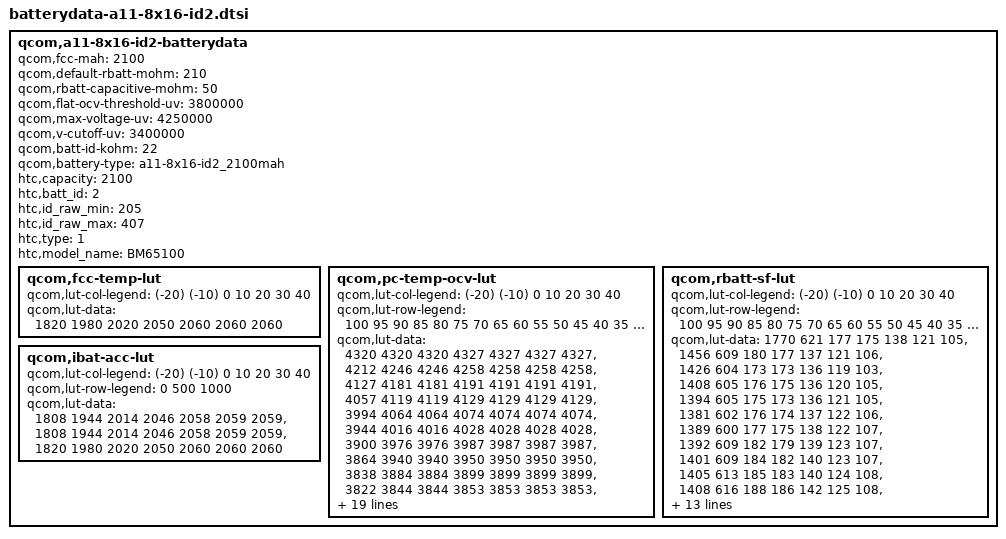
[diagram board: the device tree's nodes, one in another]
/* Copyright (c) 2013, The Linux Foundation. All rights reserved.
 *
 * This program is free software; you can redistribute it and/or modify
 * it under the terms of the GNU General Public License version 2 and
 * only version 2 as published by the Free Software Foundation.
 *
 * This program is distributed in the hope that it will be useful,
 * but WITHOUT ANY WARRANTY; without even the implied warranty of
 * MERCHANTABILITY or FITNESS FOR A PARTICULAR PURPOSE.  See the
 * GNU General Public License for more details.
 */

qcom,a11-8x16-id2-batterydata {
	qcom,fcc-mah = <2100>;
	qcom,default-rbatt-mohm = <210>;
	qcom,rbatt-capacitive-mohm = <50>;
	qcom,flat-ocv-threshold-uv = <3800000>;
	qcom,max-voltage-uv = <4250000>;
	qcom,v-cutoff-uv = <3400000>;
	qcom,batt-id-kohm = <22>;
	qcom,battery-type = "a11-8x16-id2_2100mah";
	htc,capacity = <2100>;
	htc,batt_id = <2>;
	htc,id_raw_min = <205>;
	htc,id_raw_max = <407>;
	htc,type = <1>;
	htc,model_name = "BM65100";

	qcom,fcc-temp-lut {
		qcom,lut-col-legend = <(-20) (-10) 0 10 20 30 40>;
		qcom,lut-data = <1820 1980 2020 2050 2060 2060 2060>;
	};

	qcom,pc-temp-ocv-lut {
		qcom,lut-col-legend = <(-20) (-10) 0 10 20 30 40>;
		qcom,lut-row-legend = <100 95 90 85 80 75 70 65 60 55 50 45 40 35 30 25 20 15 10 9 8 7 6 5 4 3 2 1 0>;
		qcom,lut-data = <4320 4320 4320 4327 4327 4327 4327>,
				<4212 4246 4246 4258 4258 4258 4258>,
				<4127 4181 4181 4191 4191 4191 4191>,
				<4057 4119 4119 4129 4129 4129 4129>,
				<3994 4064 4064 4074 4074 4074 4074>,
				<3944 4016 4016 4028 4028 4028 4028>,
				<3900 3976 3976 3987 3987 3987 3987>,
				<3864 3940 3940 3950 3950 3950 3950>,
				<3838 3884 3884 3899 3899 3899 3899>,
				<3822 3844 3844 3853 3853 3853 3853>,
				<3810 3820 3820 3827 3827 3827 3827>,
				<3799 3801 3801 3806 3806 3806 3806>,
				<3787 3787 3787 3789 3789 3789 3789>,
				<3778 3778 3778 3777 3777 3777 3777>,
				<3767 3767 3767 3770 3770 3770 3770>,
				<3751 3751 3751 3759 3759 3759 3759>,
				<3730 3732 3732 3736 3736 3736 3736>,
				<3702 3691 3691 3690 3690 3690 3690>,
				<3667 3629 3642 3656 3656 3656 3656>,
				<3661 3620 3632 3651 3651 3651 3651>,
				<3654 3610 3619 3647 3647 3647 3647>,
				<3645 3598 3604 3638 3638 3638 3638>,
				<3637 3585 3588 3629 3629 3629 3629>,
				<3624 3565 3565 3599 3599 3599 3599>,
				<3595 3528 3528 3568 3568 3568 3568>,
				<3567 3491 3491 3490 3490 3490 3490>,
				<3527 3440 3440 3411 3411 3411 3411>,
				<3465 3359 3359 3246 3246 3246 3246>,
				<3340 3198 3198 3081 3081 3081 3081>;
	};

	qcom,rbatt-sf-lut {
		qcom,lut-col-legend = <(-20) (-10) 0 10 20 30 40>;
		qcom,lut-row-legend = <100 95 90 85 80 75 70 65 60 55 50 45 40 35 30 25 20 15 10 8 6 4 2 0>;
		qcom,lut-data = <1770 621 177 175 138 121 105>,
						<1456 609 180 177 137 121 106>,
						<1426 604 173 173 136 119 103>,
						<1408 605 176 175 136 120 105>,
						<1394 605 175 173 136 121 105>,
						<1381 602 176 174 137 122 106>,
						<1389 600 177 175 138 122 107>,
						<1392 609 182 179 139 123 107>,
						<1401 609 184 182 140 123 107>,
						<1405 613 185 183 140 124 108>,
						<1408 616 188 186 142 125 108>,
						<1406 626 196 191 145 127 109>,
						<1415 634 203 197 148 129 111>,
						<1438 645 217 209 152 132 112>,
						<1438 660 227 217 157 135 114>,
						<1438 660 239 227 161 138 116>,
						<1438 665 254 240 168 142 118>,
						<1438 665 269 247 179 150 121>,
						<1438 670 362 286 217 180 144>,
						<1438 670 411 306 236 196 155>,
						<1438 670 514 342 270 222 175>,
						<1440 675 514 396 321 262 203>,
						<1446 680 520 450 361 295 231>,
						<1463 702 533 468 394 330 265>;
	};

	qcom,ibat-acc-lut {
		qcom,lut-col-legend = <(-20) (-10) 0 10 20 30 40>;
		qcom,lut-row-legend = <0 500 1000>;
		qcom,lut-data = <1808 1944 2014 2046 2058 2059 2059>,
						<1808 1944 2014 2046 2058 2059 2059>,
						<1820 1980 2020 2050 2060 2060 2060>;
	};
};
